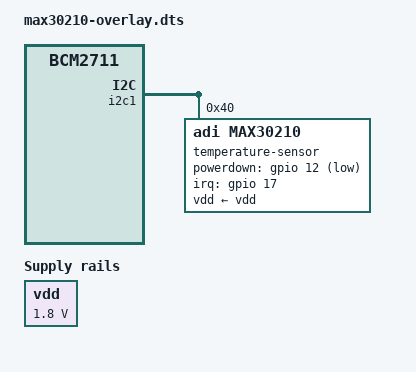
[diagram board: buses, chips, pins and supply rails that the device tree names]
// SPDX-License-Identifier: GPL-2.0
/* Overlay for MAX30210
 *
 * Copyright 2026 Analog Devices Inc.
 */

#include <dt-bindings/interrupt-controller/irq.h>
#include <dt-bindings/gpio/gpio.h>
#include <dt-bindings/pwm/pwm.h>
#include <dt-bindings/pinctrl/bcm2835.h>

 /dts-v1/;
 /plugin/;

/ {
	compatible = "bcrm, bcm2711";
};

&{/} {
	vdd: regulator {
		compatible = "regulator-fixed";
		regulator-name = "vdd";
		regulator-min-microvolt = <1800000>;
		regulator-max-microvolt = <1800000>;
		regulator-boot-on;
		regulator-always-on;
	};
};

&gpio {
	max30210_int_pins: max30210_int_pins {
		brcm,pins = <17>;
		brcm,function = <BCM2835_FSEL_GPIO_IN>;
		brcm,pull = <BCM2835_PUD_UP>;
	};
};

&i2c1 {
	#address-cells = <1>;
	#size-cells = <0>;
	status = "okay";

	temperature-sensor@40 {
		compatible = "adi,max30210";
		reg = <0x40>;
		vdd-supply = <&vdd>;
		powerdown-gpios = <&gpio 12 GPIO_ACTIVE_LOW>;

		pinctrl-names = "default";
		pinctrl-0 = <&max30210_int_pins>;

		interrupt-parent = <&gpio>;
		interrupts = <17 IRQ_TYPE_EDGE_BOTH>;

		adi,roc-en;
	};
};
